# SPC1169 register map
File version: 2022071043481212
CPU: cm4 r1p0, little endian, no MPU, FPU, 4 interrupt priority bits
Registers are 32-bit, read-write, reset 0x0 unless marked. A register's access mark holds for its fields unless they carry their own. Offsets are from the block's base; [hi:lo] are bit positions; 'fields as' and 'values as' point back to an identical list.

## DMACH0
Base 0x40001C00
Same registers: DMACH1 0x40001C58, DMACH2 0x40001CB0, DMACH3 0x40001D08, DMACH4 0x40001D60, DMACH5 0x40001DB8, DMACH6 0x40001E10, DMACH7 0x40001E68
0x00 DMACHSA — DMA Channel Source Address Register
  [31:0] ADDR — Current source address of DMA transfer. This register must be written with a 32-bit aligned address. It is updated after each source transfer according to DMACHCTL0.SINC
0x08 DMACHDA — DMA Channel Destination Address Register
  [31:0] ADDR — Current Destination address of DMA transfer. This register must be written with a 32-bit aligned address. It is updated after each source transfer according to DMACHCTL0.DINC
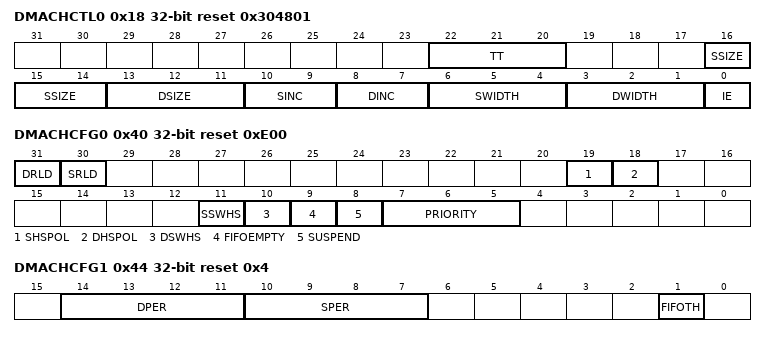
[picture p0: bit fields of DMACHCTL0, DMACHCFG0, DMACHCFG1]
0x18 DMACHCTL0 reset 0x304801 — DMA Channel Control Register 0
  [22:20] TT — Transfer type. For multi-block transfers using linked list operation, TT must be constant for all blocks of this multi-block transfer.
    0=MEM_TO_MEM (Memory to memory, DMAC is flow controller); 1=MEM_TO_PER (Memory to peripheral, DMAC is flow controller); 2=PER_TO_MEM (Peripheral to memory, DMAC is flow controller); 3=PER_TO_PER (Peripheral to peripheral, DMAC is flow controller); 4=PER_TO_MEM_SFC (Peripheral to memory, source peripheral is flow controller); 5=PER_TO_PER_SFC (Peripheral to peripheral, source peripheral is flow controller); 6=MEM_TO_PER_DFC (Memory to peripheral, destination peripheral is flow controller); 7=PER_TO_PER_DFC (Peripheral to peripheral, destination peripheral is flow controller)
  [16:14] SSIZE — Source burst transaction length. Number of data items, each of width SWIDTH, to be read from the source every time a source burst transaction request is made the corresponding handshaking interface. Note: This value is not related to the AHB master HBURST signal.
    0=1_WORD (1 word (32-bit)); 1=4_WORD (4 words); 2=8_WORD (8 words); 3=16_WORD (16 words); 4=32_WORD (32 words); 5=64_WORD (64 words); 6=128_WORD (128 words); 7=256_WORD (256 words)
  [13:11] DSIZE — Destination burst transaction length. Number of data items, each of width DWIDTH, to be written to the destination every time a destination burst transaction request is made from the corresponding handshaking interface. Note: This value is not related to the AHB master HBURST signal.
    values as SSIZE
  [10:9] SINC — Source address increment after each transfer. Incrementing or decrementing is done for alignment to the next SWIDTH boundary.
    0=INCREASE (Increase to next word aligned address); 1=DECREASE (Decrease to next word aligned address); 2=NO_CHANGE (Freeze the address)
  [8:7] DINC — Destination address increment after each transfer. Incrementing or decrementing is done for alignment to the next DWIDTH boundary.
    values as SINC
  [6:4] SWIDTH — Source transfer width. It should not exceed AHB bus HDATA width (32-bits). For a non-memory peripheral, typically the peripheral (source) FIFO width.
    0=U8 (Byte (8-bits)); 1=U16 (Half-word (16-bits)); 2=U32 (Word (32-bits)); 3=U64 (Double-word (64-bits)); 4=U128 (Four-word (128-bits)); 5=U256 (Eight-word (256-bits))
  [3:1] DWIDTH — Destination transfer width. It should not exceed AHB bus HDATA width (32-bits). For a non-memory peripheral, typically the peripheral (destination) FIFO width.
    values as SWIDTH
  [0] IE — Interrupt enable. This bit does not affect the raw interrupt flag generation
    0=DISABLE (Disable interrupt); 1=ENABLE (Enable interrupt)
0x1C DMACHCTL1 reset 0x2 — DMA Channel Control Register 1
  [11:0] BLKTS — Block transfer size. Which is the total number of single transactions to perform for every block transfer; a single transaction is mapped to a single AMBA beat. The width of the single transaction is determined by DMACHCTL0.SWIDTH. This field must be written before the channel is enabled in order to indicate the block size.
0x40 DMACHCFG0 reset 0xE00 — DMA Channel Configure Register 0
  [31] DRLD — Automatic destination reload. The DMACHDA register can be automatically reloaded from its initial value at the end of every block for multi-block transfers. A new block transfer is then initiated.
    0=DISABLE; 1=ENABLE
  [30] SRLD — Automatic source reload. The DMACHSA register can be automatically reloaded from its initial value at the end of every block for multi-block transfers. A new block transfer is then initiated.
    0=DISABLE; 1=ENABLE
  [19] SHSPOL — Source handshaking interface polarity.
    0=ACTIVE_LOW; 1=ACTIVE_HIGH
  [18] DHSPOL — Destination handshaking interface polarity.
    0=ACTIVE_LOW; 1=ACTIVE_HIGH
  [11] SSWHS — Source software handshaking select. This bit is ignored if the source is memory
    0=HARDWARE (Hardware handshaking); 1=SOFTWARE (Software handshaking)
  [10] DSWHS — Destination software handshaking select. This bit is ignored if the destination is memory
    values as SSWHS
  [9] FIFOEMPTY ro — Indicates if there is data left in the channel FIFO. Can be used in conjunction with SUSPEND bit to cleanly disable a channel.
    0=NOT_EMPTY (There is data left in the FIFO); 1=EMPTY (FIFO is fully empty)
  [8] SUSPEND — Channel suspend. Suspends all DMA data transfers from the source until this bit is cleared. There is no guarantee that the current transaction will complete. Can also be used in conjunction with FIFODAV bit to cleanly disable a channel without losing any data.
    0=DISABLE (Not suspended.); 1=ENABLE (Suspend DMA transfer from the source.)
  [7:5] PRIORITY — Channel priority. This field must be written as a value within 0 to 7 while 0 is the lowest priority
    0=8TH_PRIORITY (8th priority (Lowest)); 1=7TH_PRIORITY; 2=6TH_PRIORITY; 3=5TH_PRIORITY; 4=4TH_PRIORITY; 5=3RD_PRIORITY; 6=2ND_PRIORITY; 7=1ST_PRIORITY (1st priority (Highest))
0x44 DMACHCFG1 reset 0x4 — DMA Channel Configure Register 1
  [14:11] DPER — Destination peripheral that communicated through hardware handshaking interface. This field is ignored if DMACHCFG0.DSWHS=1.
  [10:7] SPER — Source peripheral that communicated through hardware handshaking interface. This field is ignored if DMACHCFG0.SSWHS=1.
  [1] FIFOTH — FIFO threshold to determine how much space or data needs to be available in the FIFO before a burst transaction request is serviced.
    0=SINGLE_ENTRY (Transfer whenever data or space is avaiable in the FIFO); 1=HALF_DEPTH (Destination transfer will not start until data available is greater than or equal to half the FIFO depth. Source transfer will not start until data available is greater than half the FIFO depth. The exceptions are at the end of a burst transaction request or at the end of a block transfer.)
